# nrf7120E_enga_application register map
Vendor: Nordic Semiconductor; Series: nrf71; File version: 1
CPU: CM33 r0p4, little endian, MPU, FPU, 3 interrupt priority bits, 270 interrupts, 4 SAU regions
Registers are 32-bit, read-write, reset 0x0 unless marked. A register's access mark holds for its fields unless they carry their own. Offsets are from the block's base; [hi:lo] are bit positions; lines under a group give offsets from that group; {n}, {i} and the like mark numbered series.

## GLOBAL_MPC00_S — Memory Privilege Controller 0
Base 0x50041000; alternate view of GLOBAL_USBHSCORE_S
Same registers: GLOBAL_MPC03_S 0x50043000
0x100 EVENTS_MEMACCERR — Memory Access Error event
  [0] EVENTS_MEMACCERR
    0=NotGenerated (Event not generated); 1=Generated (Event generated)
0x300 INTEN — Enable or disable interrupt
  [0] MEMACCERR — Enable or disable interrupt for event MEMACCERR
    0=Disabled; 1=Enabled
0x304 INTENSET — Enable interrupt
  [0] MEMACCERR write-1-sets — Write '1' to enable interrupt for event MEMACCERR
    on read: 0=Disabled (Read: Disabled); 1=Enabled (Read: Enabled) | on write: 1=Set (Enable)
0x308 INTENCLR — Disable interrupt
  [0] MEMACCERR write-1-clears — Write '1' to disable interrupt for event MEMACCERR
    on read: 0=Disabled (Read: Disabled); 1=Enabled (Read: Enabled) | on write: 1=Clear (Disable)
0x400 MEMACCERR group — Memory Access Error status registers
  0x00 ADDRESS ro — Target Address of Memory Access Error. Register content will not be changed as long as MEMACCERR event is active.
    [31:0] ADDRESS — Target address for erroneous access
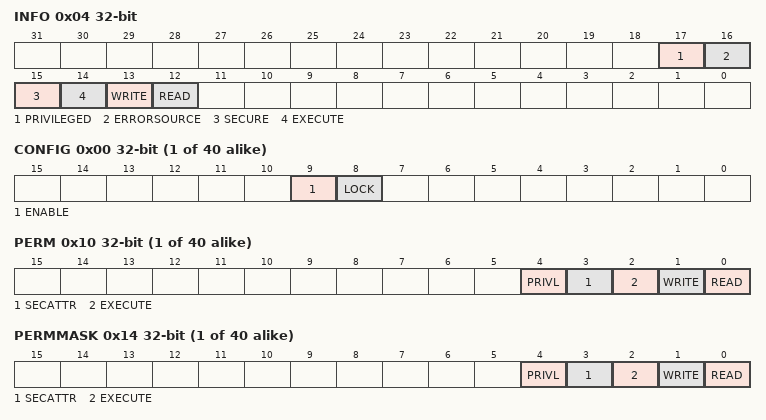
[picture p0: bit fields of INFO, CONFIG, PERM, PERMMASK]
  0x04 INFO ro — Access information for the transaction that triggered a memory access error. Register content will not be changed as long as MEMACCERR event is active.
    [17] PRIVILEGED — Privileged bit of bus access
      1=Set (Privileged bit was set); 0=NotSet (Privileged bit was not set)
    [16] ERRORSOURCE — Source of memory access error
      1=MPC (Error was triggered by MPC module); 0=Slave (Error was triggered by a Subordinate)
    [15] SECURE — Secure bit of bus access
      1=Set (Secure access bit was set); 0=NotSet (Secure access bit was not set)
    [14] EXECUTE — Execute bit of bus access
      1=Set (Execute access bit was set); 0=NotSet (Execute access bit was not set)
    [13] WRITE — Write bit of bus access
      1=Set (Write access bit was set); 0=NotSet (Write access bit was not set)
    [12] READ — Read bit of bus access
      1=Set (Read access bit was set); 0=NotSet (Read access bit was not set)
{0x800+0x20*i} OVERRIDE[{i}] (i=0..39) group — Special privilege tables
  0x00 CONFIG — Description cluster: Override region n Configuration register
    [9] ENABLE — Enable Override region n
      0=Disabled (Override region n is not used); 1=Enabled (Override region n is used)
    [8] LOCK rw-once — Lock Override region n
      0=Unlocked (Override region n settings can be updated); 1=Locked (Override region n settings can not be updated until next reset)
  0x04 STARTADDR — Description cluster: Override region n Start Address
    [31:0] STARTADDR — Start address for override region n
  0x08 ENDADDR — Description cluster: Override region n End Address
    [31:0] ENDADDR — End address for override region n
  0x0C OFFSET — Description cluster: Address offset value divided by 2 for override region n address re-map
    [31:0] OFFSET — Offset value
  0x10 PERM — Description cluster: Permission settings for override region n
    [4] PRIVL — Privileged access
      1=Privileged access only; 0=Unprivileged (Privileged and unprivileged access)
    [3] SECATTR — Security mapping
      1=Secure (Override region n is mapped in secure memory address space); 0=NonSecure (Override region n is mapped in non-secure memory address space)
    [2] EXECUTE — Software execute
      0=NotAllowed (Software execution from override region n is not allowed); 1=Allowed (Software execution from override region n is allowed)
    [1] WRITE — Write access
      0=NotAllowed (Write access to override region n is not allowed); 1=Allowed (Write access to override region n is allowed)
    [0] READ — Read access
      0=NotAllowed (Read access to override region n is not allowed); 1=Allowed (Read access to override region n is allowed)
  0x14 PERMMASK — Description cluster: Masks permission setting fields from register OVERRIDE.PERM
    [4] PRIVL — Privileged mask
      0=Masked (Permission setting PRIVL in OVERRIDE register will not be applied); 1=UnMasked (Permission setting PRIVL in OVERRIDE register will be applied)
    [3] SECATTR — Security mapping mask
      0=Masked (Permission setting SECATTR in OVERRIDE register will not be applied); 1=UnMasked (Permission setting SECATTR in OVERRIDE register will be applied)
    [2] EXECUTE — Execute mask
      0=Masked (Permission setting EXECUTE in OVERRIDE register will not be applied); 1=UnMasked (Permission setting EXECUTE in OVERRIDE register will be applied)
    [1] WRITE — Write mask
      0=Masked (Permission setting WRITE in OVERRIDE register will not be applied); 1=UnMasked (Permission setting WRITE in OVERRIDE register will be applied)
    [0] READ — Read mask
      0=Masked (Permission setting READ in OVERRIDE register will not be applied); 1=UnMasked (Permission setting READ in OVERRIDE register will be applied)
